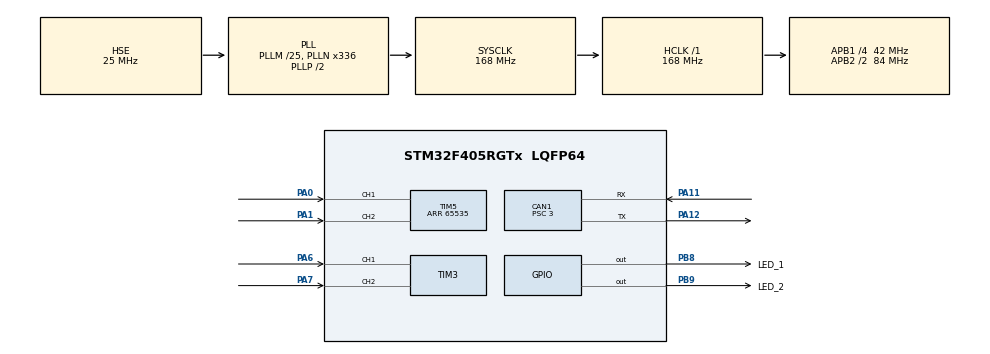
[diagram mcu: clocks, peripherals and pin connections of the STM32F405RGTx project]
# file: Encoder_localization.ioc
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CAN1.ABOM=ENABLE
CAN1.AWUM=ENABLE
CAN1.BS1=CAN_BS1_9TQ
CAN1.BS2=CAN_BS2_4TQ
CAN1.CalculateBaudRate=1000000
CAN1.CalculateTimeBit=1000
CAN1.CalculateTimeQuantum=71.42857142857143
CAN1.NART=ENABLE
CAN1.Prescaler=3
FREERTOS.Tasks01=POSI_Task,24,1024,StartPOSI_Task,As weak,NULL,Dynamic,NULL,NULL;LED_Task,8,128,StartLEDTask,As weak,NULL,Dynamic,NULL,NULL
Mcu.Family=STM32F4
Mcu.Name=STM32F405RGTx
Mcu.Package=LQFP64
NVIC.CAN1_RX0_IRQn=true\:5\:0\:true\:false\:true\:true\:true\:true\:true
NVIC.PriorityGroup=NVIC_PRIORITYGROUP_4
NVIC.TIM2_IRQn=true\:5\:0\:false\:false\:true\:true\:true\:true\:true
NVIC.TIM6_DAC_IRQn=true\:15\:0\:false\:false\:true\:false\:false\:true\:true
NVIC.TimeBase=TIM6_DAC_IRQn
NVIC.TimeBaseIP=TIM6
PA0-WKUP.Signal=S_TIM5_CH1
PA1.Signal=S_TIM5_CH2
PA11.Mode=CAN_Activate
PA11.Signal=CAN1_RX
PA12.Mode=CAN_Activate
PA12.Signal=CAN1_TX
PA13.Mode=Serial_Wire
PA13.Signal=SYS_JTMS-SWDIO
PA14.Mode=Serial_Wire
PA14.Signal=SYS_JTCK-SWCLK
PA6.Signal=S_TIM3_CH1
PA7.Signal=S_TIM3_CH2
PB8.GPIO_Label=LED_1
PB8.GPIO_PuPd=GPIO_NOPULL
PB8.PinState=GPIO_PIN_SET
PB8.Signal=GPIO_Output
PB9.GPIO_Label=LED_2
PB9.GPIO_PuPd=GPIO_NOPULL
PB9.PinState=GPIO_PIN_SET
PB9.Signal=GPIO_Output
PH0-OSC_IN.Mode=HSE-External-Oscillator
PH0-OSC_IN.Signal=RCC_OSC_IN
PH1-OSC_OUT.Mode=HSE-External-Oscillator
PH1-OSC_OUT.Signal=RCC_OSC_OUT
ProjectManager.HeapSize=0x200
ProjectManager.StackSize=0x400
ProjectManager.TargetToolchain=MDK-ARM V5.32
RCC.48MHZClocksFreq_Value=84000000
RCC.AHBFreq_Value=168000000
RCC.APB1CLKDivider=RCC_HCLK_DIV4
RCC.APB1Freq_Value=42000000
RCC.APB1TimFreq_Value=84000000
RCC.APB2CLKDivider=RCC_HCLK_DIV2
RCC.APB2Freq_Value=84000000
RCC.APB2TimFreq_Value=168000000
RCC.CortexFreq_Value=168000000
RCC.HCLKFreq_Value=168000000
RCC.HSE_VALUE=25000000
RCC.HSI_VALUE=16000000
RCC.LSE_VALUE=32768
RCC.PLLM=25
RCC.PLLN=336
RCC.PLLSourceVirtual=RCC_PLLSOURCE_HSE
RCC.SYSCLKFreq_VALUE=168000000
RCC.SYSCLKSource=RCC_SYSCLKSOURCE_PLLCLK
RCC.VCOOutputFreq_Value=336000000
SH.S_TIM3_CH1.0=TIM3_CH1,Encoder_Interface
SH.S_TIM3_CH2.0=TIM3_CH2,Encoder_Interface
SH.S_TIM5_CH1.0=TIM5_CH1,Encoder_Interface
SH.S_TIM5_CH2.0=TIM5_CH2,Encoder_Interface
TIM2.Period=100-1
TIM2.Prescaler=83
TIM3.IC1Polarity=TIM_ICPOLARITY_FALLING
TIM3.IC2Polarity=TIM_ICPOLARITY_FALLING
TIM5.IC1Polarity=TIM_ICPOLARITY_FALLING
TIM5.IC2Polarity=TIM_ICPOLARITY_FALLING
TIM5.Period=65535
VP_FREERTOS_VS_CMSIS_V2.Mode=CMSIS_V2
VP_SYS_VS_tim6.Mode=TIM6
VP_TIM2_VS_ClockSourceINT.Mode=Internal
board=custom

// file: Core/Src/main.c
/* USER CODE BEGIN Header */
/**
  ******************************************************************************
  * @file           : main.c
  * @brief          : Main program body
  ******************************************************************************
  * @attention
  *
  * Copyright (c) 2026 STMicroelectronics.
  * All rights reserved.
  *
  * This software is licensed under terms that can be found in the LICENSE file
  * in the root directory of this software component.
  * If no LICENSE file comes with this software, it is provided AS-IS.
  *
  ******************************************************************************
  */
/* USER CODE END Header */
#include "main.h"
#include "cmsis_os.h"
#include "can.h"
#include "tim.h"
#include "gpio.h"

/* USER CODE BEGIN Includes */
#include "POSI_task.h"
#include "TIM_IRQHandler.h"

volatile extern Encoder encoder[2];
/* USER CODE END Includes */

void SystemClock_Config(void);
void MX_FREERTOS_Init(void);

int main(void)
{

  /* MCU Configuration--------------------------------------------------------*/

  /* Reset of all peripherals, Initializes the Flash interface and the Systick. */
  HAL_Init();

  /* Configure the system clock */
  SystemClock_Config();

  /* Initialize all configured peripherals */
  MX_GPIO_Init();
  MX_CAN1_Init();
  MX_TIM2_Init();
  MX_TIM3_Init();
  MX_TIM5_Init();
  /* USER CODE BEGIN 2 */
  HAL_TIM_Encoder_Start(&htim3, TIM_CHANNEL_ALL);
  HAL_TIM_Encoder_Start(&htim5, TIM_CHANNEL_ALL);
  Encoder_init(&encoder[0], &htim3);
  Encoder_init(&encoder[1], &htim5);
  HAL_TIM_Base_Start_IT(&htim2);
  /* USER CODE END 2 */

  /* Init scheduler */
  osKernelInitialize();  /* Call init function for freertos objects (in cmsis_os2.c) */
  MX_FREERTOS_Init();

  /* Start scheduler */
  osKernelStart();

  /* We should never get here as control is now taken by the scheduler */

  /* Infinite loop */
  while (1)
  {

  }
}

void SystemClock_Config(void)
{
  RCC_OscInitTypeDef RCC_OscInitStruct = {0};
  RCC_ClkInitTypeDef RCC_ClkInitStruct = {0};

  /** Configure the main internal regulator output voltage
  */
  __HAL_RCC_PWR_CLK_ENABLE();
  __HAL_PWR_VOLTAGESCALING_CONFIG(PWR_REGULATOR_VOLTAGE_SCALE1);

  /** Initializes the RCC Oscillators according to the specified parameters
  * in the RCC_OscInitTypeDef structure.
  */
  RCC_OscInitStruct.OscillatorType = RCC_OSCILLATORTYPE_HSE;
  RCC_OscInitStruct.HSEState = RCC_HSE_ON;
  RCC_OscInitStruct.PLL.PLLState = RCC_PLL_ON;
  RCC_OscInitStruct.PLL.PLLSource = RCC_PLLSOURCE_HSE;
  RCC_OscInitStruct.PLL.PLLM = 25;
  RCC_OscInitStruct.PLL.PLLN = 336;
  RCC_OscInitStruct.PLL.PLLP = RCC_PLLP_DIV2;
  RCC_OscInitStruct.PLL.PLLQ = 4;
  if (HAL_RCC_OscConfig(&RCC_OscInitStruct) != HAL_OK)
  {
    Error_Handler();
  }

  /** Initializes the CPU, AHB and APB buses clocks
  */
  RCC_ClkInitStruct.ClockType = RCC_CLOCKTYPE_HCLK|RCC_CLOCKTYPE_SYSCLK
                              |RCC_CLOCKTYPE_PCLK1|RCC_CLOCKTYPE_PCLK2;
  RCC_ClkInitStruct.SYSCLKSource = RCC_SYSCLKSOURCE_PLLCLK;
  RCC_ClkInitStruct.AHBCLKDivider = RCC_SYSCLK_DIV1;
  RCC_ClkInitStruct.APB1CLKDivider = RCC_HCLK_DIV4;
  RCC_ClkInitStruct.APB2CLKDivider = RCC_HCLK_DIV2;

  if (HAL_RCC_ClockConfig(&RCC_ClkInitStruct, FLASH_LATENCY_5) != HAL_OK)
  {
    Error_Handler();
  }
}

void HAL_TIM_PeriodElapsedCallback(TIM_HandleTypeDef *htim)
{
  if (htim->Instance == TIM6)
  {
    HAL_IncTick();
  }
  /* USER CODE BEGIN Callback 1 */
  TIM_PeriodElapsedCallback(htim);
  /* USER CODE END Callback 1 */
}

void Error_Handler(void)
{
  __disable_irq();
  while (1)
  {
  }
}

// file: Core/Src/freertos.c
/* USER CODE BEGIN Header */
/**
  ******************************************************************************
  * File Name          : freertos.c
  * Description        : Code for freertos applications
  ******************************************************************************
  * @attention
  *
  * Copyright (c) 2026 STMicroelectronics.
  * All rights reserved.
  *
  * This software is licensed under terms that can be found in the LICENSE file
  * in the root directory of this software component.
  * If no LICENSE file comes with this software, it is provided AS-IS.
  *
  ******************************************************************************
  */
/* USER CODE END Header */

#include "FreeRTOS.h"
#include "task.h"
#include "main.h"
#include "cmsis_os.h"

/* Definitions for POSI_Task */
osThreadId_t POSI_TaskHandle;
const osThreadAttr_t POSI_Task_attributes = {
  .name = "POSI_Task",
  .stack_size = 1024 * 4,
  .priority = (osPriority_t) osPriorityNormal,
};
/* Definitions for LED_Task */
osThreadId_t LED_TaskHandle;
const osThreadAttr_t LED_Task_attributes = {
  .name = "LED_Task",
  .stack_size = 128 * 4,
  .priority = (osPriority_t) osPriorityLow,
};

void StartPOSI_Task(void *argument);
void StartLEDTask(void *argument);

void MX_FREERTOS_Init(void); /* (MISRA C 2004 rule 8.1) */

void MX_FREERTOS_Init(void) {

  /* Create the thread(s) */
  /* creation of POSI_Task */
  POSI_TaskHandle = osThreadNew(StartPOSI_Task, NULL, &POSI_Task_attributes);

  /* creation of LED_Task */
  LED_TaskHandle = osThreadNew(StartLEDTask, NULL, &LED_Task_attributes);

}

__weak void StartPOSI_Task(void *argument)
{
  for(;;)
  {
    osDelay(1);
  }
}

__weak void StartLEDTask(void *argument)
{
  for(;;)
  {
    osDelay(1);
  }
}
